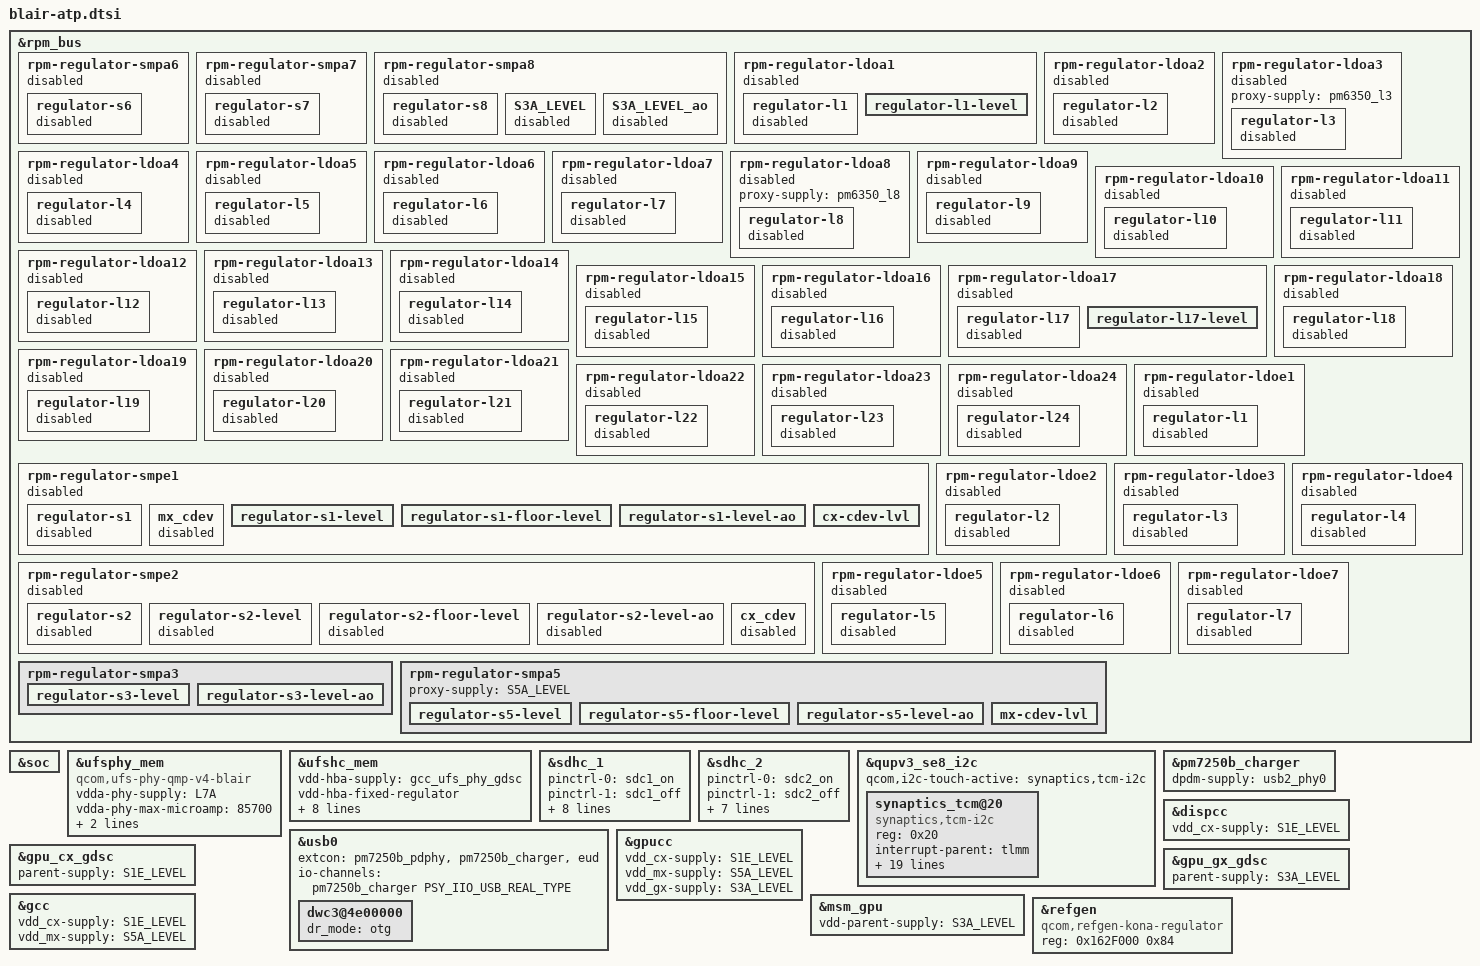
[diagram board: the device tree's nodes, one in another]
&rpm_bus {
	/* Delete all PM6125 and PMR735a rpm-regulators */
	/delete-node/ rpm-regulator-smpa6;
	/delete-node/ rpm-regulator-smpa7;
	/delete-node/ rpm-regulator-smpa8;
	/delete-node/ rpm-regulator-ldoa1;
	/delete-node/ rpm-regulator-ldoa2;
	/delete-node/ rpm-regulator-ldoa3;
	/delete-node/ rpm-regulator-ldoa4;
	/delete-node/ rpm-regulator-ldoa5;
	/delete-node/ rpm-regulator-ldoa6;
	/delete-node/ rpm-regulator-ldoa7;
	/delete-node/ rpm-regulator-ldoa8;
	/delete-node/ rpm-regulator-ldoa9;
	/delete-node/ rpm-regulator-ldoa10;
	/delete-node/ rpm-regulator-ldoa11;
	/delete-node/ rpm-regulator-ldoa12;
	/delete-node/ rpm-regulator-ldoa13;
	/delete-node/ rpm-regulator-ldoa14;
	/delete-node/ rpm-regulator-ldoa15;
	/delete-node/ rpm-regulator-ldoa16;
	/delete-node/ rpm-regulator-ldoa17;
	/delete-node/ rpm-regulator-ldoa18;
	/delete-node/ rpm-regulator-ldoa19;
	/delete-node/ rpm-regulator-ldoa20;
	/delete-node/ rpm-regulator-ldoa21;
	/delete-node/ rpm-regulator-ldoa22;
	/delete-node/ rpm-regulator-ldoa23;
	/delete-node/ rpm-regulator-ldoa24;

	/delete-node/ rpm-regulator-smpe1;
	/delete-node/ rpm-regulator-smpe2;
	/delete-node/ rpm-regulator-ldoe1;
	/delete-node/ rpm-regulator-ldoe2;
	/delete-node/ rpm-regulator-ldoe3;
	/delete-node/ rpm-regulator-ldoe4;
	/delete-node/ rpm-regulator-ldoe5;
	/delete-node/ rpm-regulator-ldoe7;

	/* Disable all PM6125 and PMR735a rpm-regulators */
	rpm-regulator-smpa6 {
		status = "disabled";
		regulator-s6 {
			status = "disabled";
		};
	};

	rpm-regulator-smpa7 {
		status = "disabled";
		regulator-s7 {
			status = "disabled";
		};
	};

	rpm-regulator-smpa8 {
		status = "disabled";
		regulator-s8 {
			status = "disabled";
		};

		S3A_LEVEL {
			status = "disabled";
		};

		S3A_LEVEL_ao {
			status = "disabled";
		};
	};

	rpm-regulator-ldoa1 {
		status = "disabled";
		regulator-l1 {
			status = "disabled";
		};

		regulator-l1-level {
			status = "disabled";
		};
	};

	rpm-regulator-ldoa2 {
		status = "disabled";
		regulator-l2 {
			status = "disabled";
		};
	};

	rpm-regulator-ldoa3 {
		status = "disabled";
		regulator-l3 {
			status = "disabled";
		};
	};

	rpm-regulator-ldoa4 {
		status = "disabled";
		regulator-l4 {
			status = "disabled";
		};
	};

	rpm-regulator-ldoa5 {
		status = "disabled";
		regulator-l5 {
			status = "disabled";
		};
	};

	rpm-regulator-ldoa6 {
		status = "disabled";
		regulator-l6 {
			status = "disabled";
		};
	};

	rpm-regulator-ldoa7 {
		status = "disabled";
		regulator-l7 {
			status = "disabled";
		};
	};

	rpm-regulator-ldoa8 {
		status = "disabled";
		regulator-l8 {
			status = "disabled";
		};
	};

	rpm-regulator-ldoa9 {
		status = "disabled";
		regulator-l9 {
			status = "disabled";
		};
	};

	rpm-regulator-ldoa10 {
		status = "disabled";
		regulator-l10 {
			status = "disabled";
		};
	};

	rpm-regulator-ldoa11 {
		status = "disabled";
		regulator-l11 {
			status = "disabled";
		};
	};

	rpm-regulator-ldoa12 {
		status = "disabled";
		regulator-l12 {
			status = "disabled";
		};
	};

	rpm-regulator-ldoa13 {
		status = "disabled";
		regulator-l13 {
			status = "disabled";
		};
	};

	rpm-regulator-ldoa14 {
		status = "disabled";
		regulator-l14 {
			status = "disabled";
		};
	};

	rpm-regulator-ldoa15 {
		status = "disabled";
		regulator-l15 {
			status = "disabled";
		};
	};

	rpm-regulator-ldoa16 {
		status = "disabled";
		regulator-l16 {
			status = "disabled";
		};
	};

	rpm-regulator-ldoa17 {
		status = "disabled";
		regulator-l17 {
			status = "disabled";
		};
	};

	rpm-regulator-ldoa18 {
		status = "disabled";
		regulator-l18 {
			status = "disabled";
		};
	};

	rpm-regulator-ldoa19 {
		status = "disabled";
		regulator-l19 {
			status = "disabled";
		};
	};

	rpm-regulator-ldoa20 {
		status = "disabled";
		regulator-l20 {
			status = "disabled";
		};
	};

	rpm-regulator-ldoa21 {
		status = "disabled";
		regulator-l21 {
			status = "disabled";
		};
	};

	rpm-regulator-ldoa22 {
		status = "disabled";
		regulator-l22 {
			status = "disabled";
		};
	};

	rpm-regulator-ldoa23 {
		status = "disabled";
		regulator-l23 {
			status = "disabled";
		};
	};

	rpm-regulator-ldoa24 {
		status = "disabled";
		regulator-l24 {
			status = "disabled";
		};
	};

	rpm-regulator-smpe1 {
		status = "disabled";
		regulator-s1 {
			status = "disabled";
		};

		mx_cdev {
			status = "disabled";
		};
	};

	rpm-regulator-smpe2 {
		status = "disabled";
		regulator-s2 {
			status = "disabled";
		};

		regulator-s2-level {
			status = "disabled";
		};

		regulator-s2-floor-level {
			status = "disabled";
		};

		regulator-s2-level-ao {
			status = "disabled";
		};

		cx_cdev {
			status = "disabled";
		};
	};

	rpm-regulator-ldoe1 {
		status = "disabled";
		regulator-l1 {
			status = "disabled";
		};
	};

	rpm-regulator-ldoe2 {
		status = "disabled";
		regulator-l2 {
			status = "disabled";
		};
	};

	rpm-regulator-ldoe3 {
		status = "disabled";
		regulator-l3 {
			status = "disabled";
		};
	};

	rpm-regulator-ldoe4 {
		status = "disabled";
		regulator-l4 {
			status = "disabled";
		};
	};

	rpm-regulator-ldoe5 {
		status = "disabled";
		regulator-l5 {
			status = "disabled";
		};
	};

	rpm-regulator-ldoe6 {
		status = "disabled";
		regulator-l6 {
			status = "disabled";
		};
	};

	rpm-regulator-ldoe7 {
		status = "disabled";
		regulator-l7 {
			status = "disabled";
		};
	};
};

#include "pm6350-rpm-regulator.dtsi"
#include "pm6150l-rpm-regulator.dtsi"
#include "blair-regulators-pm6350.dtsi"

/* Enable explicitly disabled regulator resources nodes */
&rpm_bus {
	/* Enable gfx_cdev for PM6350 */
	rpm-regulator-smpa3 {
		regulator-s3-level {
			status = "okay";
		};

		regulator-s3-level-ao {
			status = "okay";
		};
	};

	/* Enable mx_cdev for PM6350 */
	rpm-regulator-smpa5 {
		proxy-supply = <&S5A_LEVEL>;
		regulator-s5-level {
			status = "okay";
		};

		regulator-s5-floor-level {
			status = "okay";
		};

		regulator-s5-level-ao {
			status = "okay";
		};

		mx-cdev-lvl {
			status = "okay";
		};
	};

	/* Enable mx_cdev for PM6150A */
	rpm-regulator-smpe1 {
		regulator-s1-level {
			status = "okay";
		};

		regulator-s1-floor-level {
			status = "okay";
		};

		regulator-s1-level-ao {
			status = "okay";
		};

		cx-cdev-lvl {
			status = "okay";
		};
	};

	/* VDD_LPI_CX supply */
	rpm-regulator-ldoa1 {
		regulator-l1-level {
			status = "okay";
		};
	};

	rpm-regulator-ldoa3 {
		proxy-supply = <&pm6350_l3>;
	};

	rpm-regulator-ldoa8 {
		proxy-supply = <&pm6350_l8>;
	};

	/* VDD_LPI_MX supply */
	rpm-regulator-ldoa17 {
		regulator-l17-level {
			status = "okay";
		};
	};
};

#include "holi-atp-pm7250b.dtsi"

&soc {

};

#include <dt-bindings/gpio/gpio.h>
#include <dt-bindings/clock/qcom,gcc-blair.h>

&ufsphy_mem {
	compatible = "qcom,ufs-phy-qmp-v4-blair";

	/* VDDA_UFS_CORE */
	vdda-phy-supply = <&L7A>;
	vdda-phy-max-microamp = <85700>;

	/* VDDA_UFS_0_1P2 */
	vdda-pll-supply = <&L4A>;
	vdda-pll-max-microamp = <18300>;

	status = "ok";
};

&ufshc_mem {
	vdd-hba-supply = <&gcc_ufs_phy_gdsc>;
	vdd-hba-fixed-regulator;

	vcc-supply = <&L24A>;
	vcc-max-microamp = <800000>;

	vccq2-supply = <&L11A>;
	vccq2-max-microamp = <800000>;

	/* VDD_PX10 is voted for the ufs_reset_n */
	qcom,vddp-ref-clk-supply = <&L4A>;
	qcom,vddp-ref-clk-max-microamp = <100>;

	reset-gpios = <&tlmm 156 GPIO_ACTIVE_LOW>;
	resets = <&gcc GCC_UFS_PHY_BCR>;
	reset-names = "rst";

	status = "ok";
};

&sdhc_1 {
	status = "ok";

	pinctrl-names = "default", "sleep";
	pinctrl-0 = <&sdc1_on>;
	pinctrl-1 = <&sdc1_off>;

	vdd-supply = <&L24A>;
	qcom,vdd-voltage-level = <2960000 2960000>;
	qcom,vdd-current-level = <0 570000>;

	vdd-io-supply = <&L11A>;
	qcom,vdd-io-always-on;
	qcom,vdd-io-lpm-sup;
	qcom,vdd-io-voltage-level = <1800000 1800000>;
	qcom,vdd-io-current-level = <0 325000>;
};

&sdhc_2 {
	status = "ok";

	pinctrl-names = "default", "sleep";
	pinctrl-0 = <&sdc2_on>;
	pinctrl-1 = <&sdc2_off>;

	vdd-supply = <&L22A>;
	qcom,vdd-voltage-level = <2960000 2960000>;
	qcom,vdd-current-level = <0 800000>;

	vdd-io-supply = <&L5A>;
	qcom,vdd-io-voltage-level = <1800000 2960000>;
	qcom,vdd-io-current-level = <0 22000>;

	cd-gpios = <&tlmm 94 GPIO_ACTIVE_LOW>;
};

&qupv3_se8_i2c {
	#address-cells = <1>;
	#size-cells = <0>;
	status = "okay";
	qcom,i2c-touch-active= "synaptics,tcm-i2c";

	synaptics_tcm@20 {
		compatible = "synaptics,tcm-i2c";
		reg = <0x20>;
		interrupt-parent = <&tlmm>;
		interrupts = <22 0x2008>;
		pinctrl-names = "pmx_ts_active","pmx_ts_suspend",
					"pmx_ts_release";
		pinctrl-0 = <&ts_active>;
		pinctrl-1 = <&ts_int_suspend &ts_reset_suspend>;
		pinctrl-2 = <&pmx_ts_release>;
		vdd-supply = <&L11A>;
		avdd-supply = <&L6A>;
		synaptics,pwr-reg-name = "avdd";
		synaptics,bus-reg-name = "vdd";
		synaptics,irq-gpio = <&tlmm 22 0x2008>;
		synaptics,irq-on-state = <0>;
		synaptics,reset-gpio = <&tlmm 21 0x00>;
		synaptics,reset-on-state = <0>;
		synaptics,reset-active-ms = <20>;
		synaptics,reset-delay-ms = <200>;
		synaptics,power-delay-ms = <200>;
		synaptics,ubl-i2c-addr = <0x20>;
		synaptics,extend_report;
		synaptics,firmware-name = "synaptics_firmware.img";
	};
};

&pm7250b_charger {
	dpdm-supply = <&usb2_phy0>;
};

&usb0 {
	extcon = <&pm7250b_pdphy>, <&pm7250b_charger>, <&eud>;
	#io-channel-cells = <1>;
	io-channels= <&pm7250b_charger PSY_IIO_USB_REAL_TYPE>;
	io-channel-names = "chg_type";

	dwc3@4e00000 {
		dr_mode = "otg";
	};

};

&dispcc {
	vdd_cx-supply = <&S1E_LEVEL>; /* VDD_CX_LEVEL */
};

&gpucc {
	vdd_cx-supply = <&S1E_LEVEL>; /* VDD_CX_LEVEL */
	vdd_mx-supply = <&S5A_LEVEL>; /* VDD_MX_LEVEL */
	vdd_gx-supply = <&S3A_LEVEL>; /* VDD_GFX_LEVEL */
};

&gpu_cx_gdsc {
	parent-supply = <&S1E_LEVEL>; /* VDD_CX_LEVEL */
};

&gpu_gx_gdsc {
	parent-supply = <&S3A_LEVEL>; /* VDD_GFX_LEVEL */
};

&gcc {
	vdd_cx-supply = <&S1E_LEVEL>; /* VDD_CX_LEVEL */
	vdd_mx-supply = <&S5A_LEVEL>; /* VDD_MX_LEVEL */
};

&msm_gpu {
	vdd-parent-supply = <&S3A_LEVEL>; /* VDD_GFX_LEVEL */
};

&refgen {
	compatible = "qcom,refgen-kona-regulator";
	reg = <0x162F000 0x84>;
};
